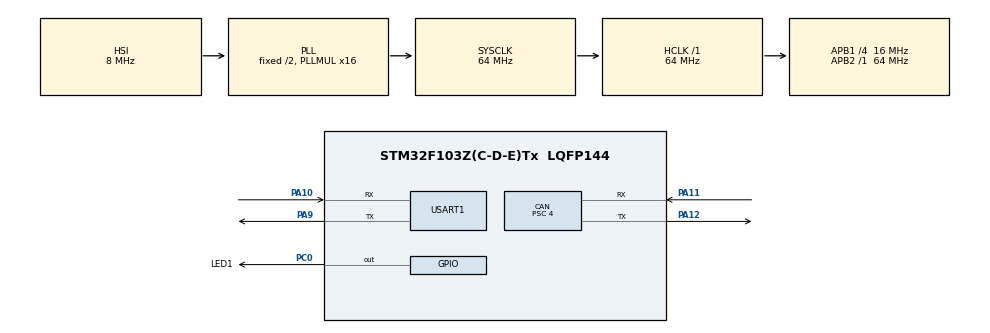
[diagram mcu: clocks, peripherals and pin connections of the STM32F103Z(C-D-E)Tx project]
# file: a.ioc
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CAN.ABOM=ENABLE
CAN.BS1=CAN_BS1_5TQ
CAN.BS2=CAN_BS2_2TQ
CAN.CalculateBaudRate=500000
CAN.CalculateTimeBit=2000
CAN.CalculateTimeQuantum=250.0
CAN.Prescaler=4
Dma.Request0=USART1_TX
Dma.USART1_TX.0.Direction=DMA_MEMORY_TO_PERIPH
Dma.USART1_TX.0.Instance=DMA1_Channel4
Dma.USART1_TX.0.MemDataAlignment=DMA_MDATAALIGN_BYTE
Dma.USART1_TX.0.MemInc=DMA_MINC_ENABLE
Dma.USART1_TX.0.Mode=DMA_NORMAL
Dma.USART1_TX.0.PeriphDataAlignment=DMA_PDATAALIGN_BYTE
Dma.USART1_TX.0.PeriphInc=DMA_PINC_DISABLE
Dma.USART1_TX.0.Priority=DMA_PRIORITY_LOW
IWDG.Prescaler=IWDG_PRESCALER_8
IWDG.Reload=2500
Mcu.Family=STM32F1
Mcu.Name=STM32F103Z(C-D-E)Tx
Mcu.Package=LQFP144
NVIC.CAN1_RX1_IRQn=true\:0\:0\:false\:false\:true\:true\:true\:true
NVIC.DMA1_Channel4_IRQn=true\:0\:0\:false\:false\:true\:false\:true\:true
NVIC.PriorityGroup=NVIC_PRIORITYGROUP_4
NVIC.USB_LP_CAN1_RX0_IRQn=true\:0\:0\:false\:false\:true\:true\:true\:true
PA10.Mode=Asynchronous
PA10.Signal=USART1_RX
PA11.Mode=CAN_Activate
PA11.Signal=CAN_RX
PA12.Mode=CAN_Activate
PA12.Signal=CAN_TX
PA13.Mode=Serial_Wire
PA13.Signal=SYS_JTMS-SWDIO
PA14.Mode=Serial_Wire
PA14.Signal=SYS_JTCK-SWCLK
PA9.Mode=Asynchronous
PA9.Signal=USART1_TX
PC0.GPIO_Label=LED1
PC0.Signal=GPIO_Output
ProjectManager.HeapSize=0x200
ProjectManager.StackSize=0x400
ProjectManager.TargetToolchain=CMake
RCC.AHBFreq_Value=64000000
RCC.APB1CLKDivider=RCC_HCLK_DIV4
RCC.APB1Freq_Value=16000000
RCC.APB1TimFreq_Value=32000000
RCC.APB2Freq_Value=64000000
RCC.APB2TimFreq_Value=64000000
RCC.HCLKFreq_Value=64000000
RCC.PLLMUL=RCC_PLL_MUL16
RCC.SYSCLKFreq_VALUE=64000000
RCC.SYSCLKSource=RCC_SYSCLKSOURCE_PLLCLK
RCC.USBFreq_Value=64000000
USART1.VirtualMode=VM_ASYNC
VP_IWDG_VS_IWDG.Mode=IWDG_Activate
board=custom

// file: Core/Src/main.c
/* USER CODE BEGIN Header */
/**
  ******************************************************************************
  * @file           : main.c
  * @brief          : Main program body
  ******************************************************************************
  * @attention
  *
  * Copyright (c) 2025 STMicroelectronics.
  * All rights reserved.
  *
  * This software is licensed under terms that can be found in the LICENSE file
  * in the root directory of this software component.
  * If no LICENSE file comes with this software, it is provided AS-IS.
  *
  ******************************************************************************
  */
/* USER CODE END Header */
#include "main.h"
#include "can.h"
#include "dma.h"
#include "iwdg.h"
#include "usart.h"
#include "gpio.h"

/* USER CODE BEGIN Includes */
#include "aes_cmac.h"
/* USER CODE END Includes */

void SystemClock_Config(void);

int main(void)
{

  /* MCU Configuration--------------------------------------------------------*/

  /* Reset of all peripherals, Initializes the Flash interface and the Systick. */
  HAL_Init();

  /* Configure the system clock */
  SystemClock_Config();

  /* Initialize all configured peripherals */
  MX_GPIO_Init();
  MX_DMA_Init();
  MX_USART1_UART_Init();
  MX_CAN_Init();
  MX_IWDG_Init();
  /* USER CODE BEGIN 2 */
  CAN_Filter_Config();
  uint8_t tx_data[8] = {0x11, 0x22, 0x33, 0x44, 0x55, 0x66, 0x77, 0x88};
  HAL_UART_Transmit(&huart1, tx_data, sizeof(tx_data), 0xFFFF);
  /* USER CODE END 2 */

  /* Infinite loop */
  while (1)
  {

    /* USER CODE BEGIN 3 */

    // CAN_Send_Message(0x123, tx_data, 8);
    // CAN_Receive_and_Reply();
    HAL_IWDG_Refresh(&hiwdg);  //watch dog 500ms timeout
    HAL_GPIO_TogglePin(LED1_GPIO_Port, LED1_Pin); // LED翻转
    HAL_Delay(200); // 延时200毫秒
  }
  /* USER CODE END 3 */
}

void SystemClock_Config(void)
{
  RCC_OscInitTypeDef RCC_OscInitStruct = {0};
  RCC_ClkInitTypeDef RCC_ClkInitStruct = {0};

  /** Initializes the RCC Oscillators according to the specified parameters
  * in the RCC_OscInitTypeDef structure.
  */
  RCC_OscInitStruct.OscillatorType = RCC_OSCILLATORTYPE_HSI|RCC_OSCILLATORTYPE_LSI;
  RCC_OscInitStruct.HSIState = RCC_HSI_ON;
  RCC_OscInitStruct.HSICalibrationValue = RCC_HSICALIBRATION_DEFAULT;
  RCC_OscInitStruct.LSIState = RCC_LSI_ON;
  RCC_OscInitStruct.PLL.PLLState = RCC_PLL_ON;
  RCC_OscInitStruct.PLL.PLLSource = RCC_PLLSOURCE_HSI_DIV2;
  RCC_OscInitStruct.PLL.PLLMUL = RCC_PLL_MUL16;
  if (HAL_RCC_OscConfig(&RCC_OscInitStruct) != HAL_OK)
  {
    Error_Handler();
  }

  /** Initializes the CPU, AHB and APB buses clocks
  */
  RCC_ClkInitStruct.ClockType = RCC_CLOCKTYPE_HCLK|RCC_CLOCKTYPE_SYSCLK
                              |RCC_CLOCKTYPE_PCLK1|RCC_CLOCKTYPE_PCLK2;
  RCC_ClkInitStruct.SYSCLKSource = RCC_SYSCLKSOURCE_PLLCLK;
  RCC_ClkInitStruct.AHBCLKDivider = RCC_SYSCLK_DIV1;
  RCC_ClkInitStruct.APB1CLKDivider = RCC_HCLK_DIV4;
  RCC_ClkInitStruct.APB2CLKDivider = RCC_HCLK_DIV1;

  if (HAL_RCC_ClockConfig(&RCC_ClkInitStruct, FLASH_LATENCY_2) != HAL_OK)
  {
    Error_Handler();
  }
}

void Error_Handler(void)
{
  __disable_irq();
  while (1)
  {
  }
}
